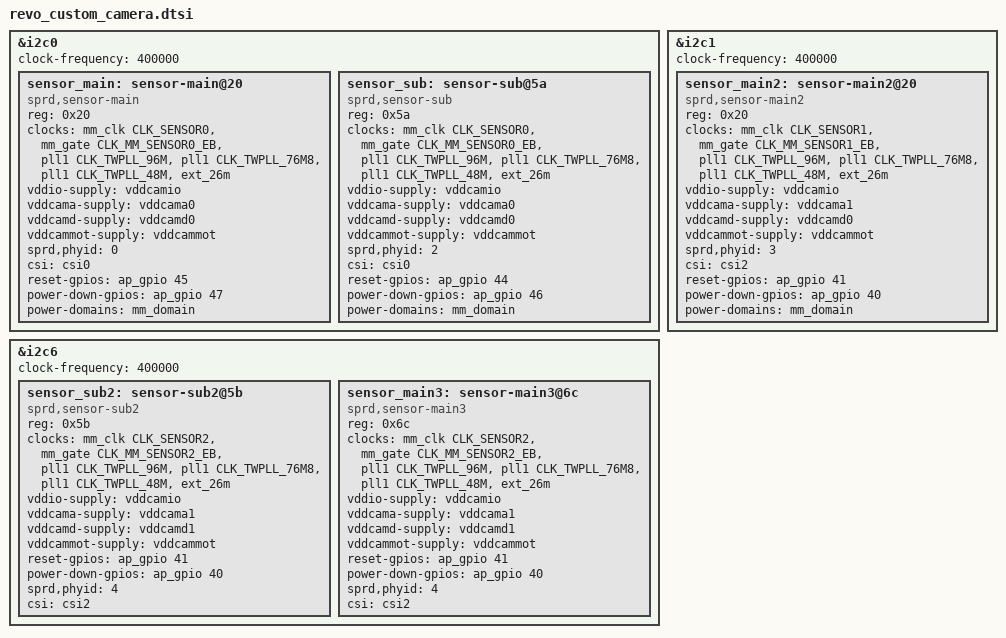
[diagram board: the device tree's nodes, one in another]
&i2c0 {
	status = "okay";
	clock-frequency = <400000>;
	#address-cells = <1>;
	#size-cells = <0>;

	sensor_main: sensor-main@20 {
		compatible = "sprd,sensor-main";
		reg = <0x20>;

		clock-names = "clk_src","sensor_eb",
			"clk_96m","clk_76m8",
			"clk_48m","clk_26m";
		clocks = <&mm_clk CLK_SENSOR0>,<&mm_gate CLK_MM_SENSOR0_EB>,
				<&pll1 CLK_TWPLL_96M>,<&pll1 CLK_TWPLL_76M8>,
				<&pll1 CLK_TWPLL_48M>,<&ext_26m>;
		vddio-supply = <&vddcamio>;
		vddcama-supply = <&vddcama0>;
		vddcamd-supply = <&vddcamd0>;
		vddcammot-supply = <&vddcammot>;
		sprd,phyid = <0>;
		csi = <&csi0>;
		reset-gpios = <&ap_gpio 45 0>;
		power-down-gpios = <&ap_gpio 47 0>;
		power-domains = <&mm_domain>;

	};

	sensor_sub: sensor-sub@5a {
		compatible = "sprd,sensor-sub";
		reg = <0x5a>;
		clock-names = "clk_src","sensor_eb",
			"clk_96m","clk_76m8",
			"clk_48m","clk_26m";
		clocks = <&mm_clk CLK_SENSOR0>,<&mm_gate CLK_MM_SENSOR0_EB>,
				<&pll1 CLK_TWPLL_96M>,<&pll1 CLK_TWPLL_76M8>,
				<&pll1 CLK_TWPLL_48M>,<&ext_26m>;
		vddio-supply = <&vddcamio>;
		vddcama-supply = <&vddcama0>;
		vddcamd-supply = <&vddcamd0>;
		vddcammot-supply = <&vddcammot>;
		sprd,phyid = <2>;
		csi = <&csi0>;
		reset-gpios = <&ap_gpio 44 0>;
		power-down-gpios = <&ap_gpio 46 0>;
		power-domains = <&mm_domain>;
	};
};

&i2c1 {
	status = "okay";
	clock-frequency = <400000>;
	#address-cells = <1>;
	#size-cells = <0>;

	sensor_main2: sensor-main2@20 {
		compatible = "sprd,sensor-main2";
		reg = <0x20>;
		clock-names = "clk_src","sensor_eb",
			"clk_96m","clk_76m8",
			"clk_48m","clk_26m";
		clocks = <&mm_clk CLK_SENSOR1>,<&mm_gate CLK_MM_SENSOR1_EB>,
				<&pll1 CLK_TWPLL_96M>,<&pll1 CLK_TWPLL_76M8>,
				<&pll1 CLK_TWPLL_48M>,<&ext_26m>;
		vddio-supply = <&vddcamio>;
		vddcama-supply = <&vddcama1>;
		vddcamd-supply = <&vddcamd0>;
		vddcammot-supply = <&vddcammot>;
		sprd,phyid = <3>;
		csi = <&csi2>;
		reset-gpios = <&ap_gpio 41 0>;
		power-down-gpios = <&ap_gpio 40 0>;
		power-domains = <&mm_domain>;
	};
};

&i2c6 {
	status = "okay";
	clock-frequency = <400000>;
	#address-cells = <1>;
	#size-cells = <0>;

	sensor_sub2: sensor-sub2@5b {
		compatible = "sprd,sensor-sub2";
		reg = <0x5b>;
		clock-names = "clk_src","sensor_eb",
			"clk_96m","clk_76m8",
			"clk_48m","clk_26m";
		clocks = <&mm_clk CLK_SENSOR2>,<&mm_gate CLK_MM_SENSOR2_EB>,
				<&pll1 CLK_TWPLL_96M>,<&pll1 CLK_TWPLL_76M8>,
				<&pll1 CLK_TWPLL_48M>,<&ext_26m>;
		vddio-supply = <&vddcamio>;
		vddcama-supply = <&vddcama1>;
		vddcamd-supply = <&vddcamd1>;
		vddcammot-supply = <&vddcammot>;
		reset-gpios = <&ap_gpio 41 0>;
		power-down-gpios = <&ap_gpio 40 0>;
		sprd,phyid = <4>;
		csi = <&csi2>;
	};
	
	sensor_main3: sensor-main3@6c {
		compatible = "sprd,sensor-main3";
		reg = <0x6c>;
		clock-names = "clk_src","sensor_eb",
			"clk_96m","clk_76m8",
			"clk_48m","clk_26m";
		clocks = <&mm_clk CLK_SENSOR2>,<&mm_gate CLK_MM_SENSOR2_EB>,
				<&pll1 CLK_TWPLL_96M>,<&pll1 CLK_TWPLL_76M8>,
				<&pll1 CLK_TWPLL_48M>,<&ext_26m>;
		vddio-supply = <&vddcamio>;
		vddcama-supply = <&vddcama1>;
		vddcamd-supply = <&vddcamd1>;
		vddcammot-supply = <&vddcammot>;
		reset-gpios = <&ap_gpio 41 0>;
		power-down-gpios = <&ap_gpio 40 0>;
		sprd,phyid = <4>;
		csi = <&csi2>;
	};
};
